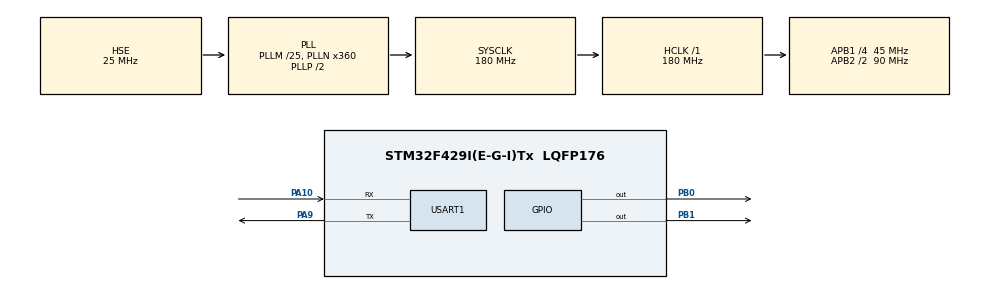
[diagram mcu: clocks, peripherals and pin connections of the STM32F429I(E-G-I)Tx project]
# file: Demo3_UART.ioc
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Mcu.Family=STM32F4
Mcu.Name=STM32F429I(E-G-I)Tx
Mcu.Package=LQFP176
NVIC.PriorityGroup=NVIC_PRIORITYGROUP_2
NVIC.USART1_IRQn=true\:3\:3\:true\:false\:true
PA10.Mode=Asynchronous
PA10.Signal=USART1_RX
PA9.Mode=Asynchronous
PA9.Signal=USART1_TX
PB0.GPIO_PuPd=GPIO_PULLUP
PB0.GPIO_Speed=GPIO_SPEED_FREQ_LOW
PB0.PinState=GPIO_PIN_SET
PB0.Signal=GPIO_Output
PB1.GPIO_PuPd=GPIO_PULLUP
PB1.GPIO_Speed=GPIO_SPEED_FREQ_LOW
PB1.PinState=GPIO_PIN_SET
PB1.Signal=GPIO_Output
PH0/OSC_IN.Mode=HSE-External-Oscillator
PH0/OSC_IN.Signal=RCC_OSC_IN
PH1/OSC_OUT.Mode=HSE-External-Oscillator
PH1/OSC_OUT.Signal=RCC_OSC_OUT
ProjectManager.HeapSize=0x200
ProjectManager.StackSize=0x400
ProjectManager.TargetToolchain=MDK-ARM V5
RCC.48MHZClocksFreq_Value=90000000
RCC.AHBFreq_Value=180000000
RCC.APB1CLKDivider=RCC_HCLK_DIV4
RCC.APB1Freq_Value=45000000
RCC.APB1TimFreq_Value=90000000
RCC.APB2CLKDivider=RCC_HCLK_DIV2
RCC.APB2Freq_Value=90000000
RCC.APB2TimFreq_Value=180000000
RCC.CortexFreq_Value=180000000
RCC.HCLKFreq_Value=180000000
RCC.HSE_VALUE=25000000
RCC.HSI_VALUE=16000000
RCC.LSE_VALUE=32768
RCC.PLLM=25
RCC.PLLN=360
RCC.PLLSourceVirtual=RCC_PLLSOURCE_HSE
RCC.SYSCLKFreq_VALUE=180000000
RCC.SYSCLKSource=RCC_SYSCLKSOURCE_PLLCLK
RCC.VCOOutputFreq_Value=360000000
board=Demo3_UART

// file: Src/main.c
/**
  ******************************************************************************
  * File Name          : main.c
  * Description        : Main program body
  ******************************************************************************
  *
  * COPYRIGHT(c) 2021 STMicroelectronics
  *
  * Redistribution and use in source and binary forms, with or without modification,
  * are permitted provided that the following conditions are met:
  *   1. Redistributions of source code must retain the above copyright notice,
  *      this list of conditions and the following disclaimer.
  *   2. Redistributions in binary form must reproduce the above copyright notice,
  *      this list of conditions and the following disclaimer in the documentation
  *      and/or other materials provided with the distribution.
  *   3. Neither the name of STMicroelectronics nor the names of its contributors
  *      may be used to endorse or promote products derived from this software
  *      without specific prior written permission.
  *
  * THIS SOFTWARE IS PROVIDED BY THE COPYRIGHT HOLDERS AND CONTRIBUTORS "AS IS"
  * AND ANY EXPRESS OR IMPLIED WARRANTIES, INCLUDING, BUT NOT LIMITED TO, THE
  * IMPLIED WARRANTIES OF MERCHANTABILITY AND FITNESS FOR A PARTICULAR PURPOSE ARE
  * DISCLAIMED. IN NO EVENT SHALL THE COPYRIGHT HOLDER OR CONTRIBUTORS BE LIABLE
  * FOR ANY DIRECT, INDIRECT, INCIDENTAL, SPECIAL, EXEMPLARY, OR CONSEQUENTIAL
  * DAMAGES (INCLUDING, BUT NOT LIMITED TO, PROCUREMENT OF SUBSTITUTE GOODS OR
  * SERVICES; LOSS OF USE, DATA, OR PROFITS; OR BUSINESS INTERRUPTION) HOWEVER
  * CAUSED AND ON ANY THEORY OF LIABILITY, WHETHER IN CONTRACT, STRICT LIABILITY,
  * OR TORT (INCLUDING NEGLIGENCE OR OTHERWISE) ARISING IN ANY WAY OUT OF THE USE
  * OF THIS SOFTWARE, EVEN IF ADVISED OF THE POSSIBILITY OF SUCH DAMAGE.
  *
  ******************************************************************************
  */
#include "stm32f4xx_hal.h"
#include "queue.h"
#include "sys.h"
#include "delay.h"

extern Queue queueRx;
/* USER CODE BEGIN PV */
/* Private variables ---------------------------------------------------------*/

/* USER CODE END PV */

void SystemClock_Config(void);
static void MX_GPIO_Init(void);
static void MX_USART1_UART_Init(void);

/* USER CODE BEGIN PFP */
/* Private function prototypes -----------------------------------------------*/

/* USER CODE END PFP */

int main(void)
{

    /* MCU Configuration----------------------------------------------------------*/

    /* Reset of all peripherals, Initializes the Flash interface and the Systick. */
    HAL_Init();

    /* Configure the system clock */
    SystemClock_Config();

    /* Initialize all configured peripherals */
    MX_GPIO_Init();
    MX_USART1_UART_Init();

    /* USER CODE BEGIN 2 */
    InitQueue(&queueRx);
    printf("hello, world!\n");
    /* USER CODE END 2 */

    /* Infinite loop */
    /* USER CODE BEGIN WHILE */
    while (1)
    {
        uint8_t temp = 0;
        /* USER CODE END WHILE */
        while (DeQueue(&queueRx, &temp))
        {
            while ((USART1->SR & USART_SR_TXE) == 0)
                ;
            USART1->DR = temp;
        }
        PBout.bit0=0;
        PBout.bit1=1;
        delay_ms(20);
        PBout.bit0=1;
        PBout.bit1=0;
        delay_ms(20);

    }
}

/** System Clock Configuration
*/
void SystemClock_Config(void)
{

    RCC_OscInitTypeDef RCC_OscInitStruct;
    RCC_ClkInitTypeDef RCC_ClkInitStruct;

    __HAL_RCC_PWR_CLK_ENABLE();

    __HAL_PWR_VOLTAGESCALING_CONFIG(PWR_REGULATOR_VOLTAGE_SCALE1);

    RCC_OscInitStruct.OscillatorType = RCC_OSCILLATORTYPE_HSE;
    RCC_OscInitStruct.HSEState = RCC_HSE_ON;
    RCC_OscInitStruct.PLL.PLLState = RCC_PLL_ON;
    RCC_OscInitStruct.PLL.PLLSource = RCC_PLLSOURCE_HSE;
    RCC_OscInitStruct.PLL.PLLM = 25;
    RCC_OscInitStruct.PLL.PLLN = 360;
    RCC_OscInitStruct.PLL.PLLP = RCC_PLLP_DIV2;
    RCC_OscInitStruct.PLL.PLLQ = 4;
    HAL_RCC_OscConfig(&RCC_OscInitStruct);

    HAL_PWREx_EnableOverDrive();

    RCC_ClkInitStruct.ClockType = RCC_CLOCKTYPE_HCLK | RCC_CLOCKTYPE_SYSCLK | RCC_CLOCKTYPE_PCLK1 | RCC_CLOCKTYPE_PCLK2;
    RCC_ClkInitStruct.SYSCLKSource = RCC_SYSCLKSOURCE_PLLCLK;
    RCC_ClkInitStruct.AHBCLKDivider = RCC_SYSCLK_DIV1;
    RCC_ClkInitStruct.APB1CLKDivider = RCC_HCLK_DIV4;
    RCC_ClkInitStruct.APB2CLKDivider = RCC_HCLK_DIV2;
    HAL_RCC_ClockConfig(&RCC_ClkInitStruct, FLASH_LATENCY_5);

    HAL_SYSTICK_Config(HAL_RCC_GetHCLKFreq() / 1000);

    HAL_SYSTICK_CLKSourceConfig(SYSTICK_CLKSOURCE_HCLK);

    /* SysTick_IRQn interrupt configuration */
    HAL_NVIC_SetPriority(SysTick_IRQn, 0, 0);
}

/* USART1 init function */
void MX_USART1_UART_Init(void)
{
    UART_HandleTypeDef huart1; //将全局变量添加到此
    huart1.Instance = USART1;
    huart1.Init.BaudRate = 115200;
    huart1.Init.WordLength = UART_WORDLENGTH_8B;
    huart1.Init.StopBits = UART_STOPBITS_1;
    huart1.Init.Parity = UART_PARITY_NONE;
    huart1.Init.Mode = UART_MODE_TX_RX;
    huart1.Init.HwFlowCtl = UART_HWCONTROL_NONE;
    huart1.Init.OverSampling = UART_OVERSAMPLING_16;
    HAL_UART_Init(&huart1);

    __HAL_UART_ENABLE_IT(&huart1, UART_IT_RXNE); //开启接收中断
}

/** Configure pins as
        * Analog
        * Input
        * Output
        * EVENT_OUT
        * EXTI
*/
void MX_GPIO_Init(void)
{

    GPIO_InitTypeDef GPIO_InitStruct;

    /* GPIO Ports Clock Enable */
    __HAL_RCC_GPIOH_CLK_ENABLE();
    __HAL_RCC_GPIOB_CLK_ENABLE();
    __HAL_RCC_GPIOA_CLK_ENABLE();

    /*Configure GPIO pin Output Level */
    HAL_GPIO_WritePin(GPIOB, GPIO_PIN_0 | GPIO_PIN_1, GPIO_PIN_SET);

    /*Configure GPIO pins : PB0 PB1 */
    GPIO_InitStruct.Pin = GPIO_PIN_0 | GPIO_PIN_1;
    GPIO_InitStruct.Mode = GPIO_MODE_OUTPUT_PP;
    GPIO_InitStruct.Pull = GPIO_PULLUP;
    GPIO_InitStruct.Speed = GPIO_SPEED_FREQ_LOW;
    HAL_GPIO_Init(GPIOB, &GPIO_InitStruct);
}

/************************ (C) COPYRIGHT STMicroelectronics *****END OF FILE****/
